VERSION "1.0"

NS_ :

BS_:

BU_: Engine ECU

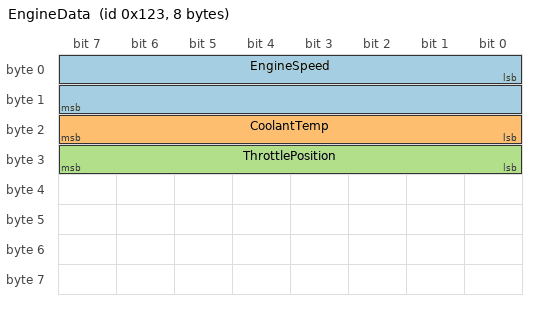
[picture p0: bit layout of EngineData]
BO_ 291 EngineData: 8 Engine
 SG_ EngineSpeed : 0|16@1+ (0.25,0) [0|16383.75] "rpm" ECU
 SG_ CoolantTemp : 16|8@1+ (1,-40) [-40|215] "degC" ECU
 SG_ ThrottlePosition : 24|8@1+ (0.39215686,0) [0|100] "%" ECU

CM_ BO_ 291 "Primary engine broadcast frame";
CM_ SG_ 291 EngineSpeed "Crank-shaft speed";
